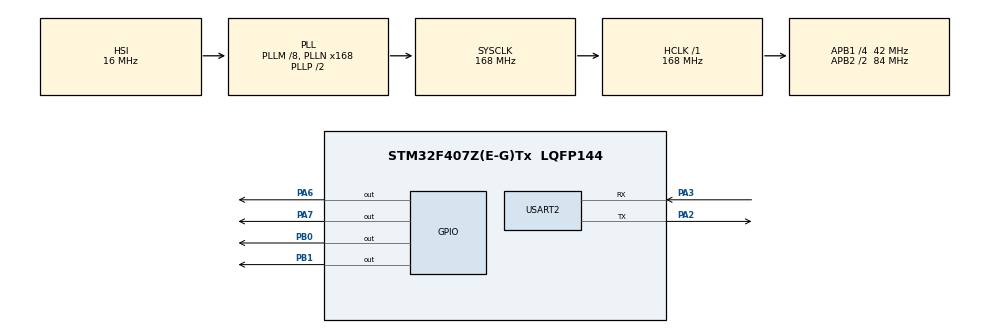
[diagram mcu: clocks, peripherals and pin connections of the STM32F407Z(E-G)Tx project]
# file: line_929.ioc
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Mcu.Family=STM32F4
Mcu.Name=STM32F407Z(E-G)Tx
Mcu.Package=LQFP144
NVIC.PriorityGroup=NVIC_PRIORITYGROUP_4
NVIC.USART2_IRQn=true\:5\:0\:false\:false\:true\:true\:true\:true
PA13.Mode=Serial_Wire
PA13.Signal=SYS_JTMS-SWDIO
PA14.Mode=Serial_Wire
PA14.Signal=SYS_JTCK-SWCLK
PA2.Mode=Asynchronous
PA2.Signal=USART2_TX
PA3.Mode=Asynchronous
PA3.Signal=USART2_RX
PA6.Signal=GPIO_Output
PA7.Signal=GPIO_Output
PB0.Signal=GPIO_Output
PB1.Signal=GPIO_Output
ProjectManager.HeapSize=0x200
ProjectManager.StackSize=0x400
ProjectManager.TargetToolchain=CMake
RCC.48MHZClocksFreq_Value=48000000
RCC.AHBFreq_Value=168000000
RCC.APB1CLKDivider=RCC_HCLK_DIV4
RCC.APB1Freq_Value=42000000
RCC.APB1TimFreq_Value=84000000
RCC.APB2CLKDivider=RCC_HCLK_DIV2
RCC.APB2Freq_Value=84000000
RCC.APB2TimFreq_Value=168000000
RCC.CortexFreq_Value=168000000
RCC.HSE_VALUE=25000000
RCC.HSI_VALUE=16000000
RCC.LSE_VALUE=32768
RCC.PLLM=8
RCC.PLLN=168
RCC.PLLQ=7
RCC.SYSCLKFreq_VALUE=168000000
RCC.SYSCLKSource=RCC_SYSCLKSOURCE_PLLCLK
RCC.VCOOutputFreq_Value=336000000
USART2.VirtualMode=VM_ASYNC
board=custom

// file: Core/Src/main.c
/* USER CODE BEGIN Header */
/**
  ******************************************************************************
  * @file           : main.c
  * @brief          : Main program body
  ******************************************************************************
  * @attention
  *
  * Copyright (c) 2026 STMicroelectronics.
  * All rights reserved.
  *
  * This software is licensed under terms that can be found in the LICENSE file
  * in the root directory of this software component.
  * If no LICENSE file comes with this software, it is provided AS-IS.
  *
  ******************************************************************************
  */
/* USER CODE END Header */
#include "main.h"
#include "usart.h"
#include "gpio.h"

/* USER CODE BEGIN Includes */
#include "oneone_app.h"
#include "oneone_dshot.h"

/* USER CODE END Includes */

/* USER CODE BEGIN PV */
/* Inspect in debugger if the startup banner never appears. */
volatile uint32_t line_929_boot_step = 0U;

/* USER CODE END PV */

void SystemClock_Config(void);

int main(void)
{

  /* MCU Configuration--------------------------------------------------------*/

  /* Reset of all peripherals, Initializes the Flash interface and the Systick. */
  HAL_Init();
  line_929_boot_step = 1U;

  /* Configure the system clock */
  SystemClock_Config();
  line_929_boot_step = 2U;

  /* Initialize all configured peripherals */
  MX_GPIO_Init();
  line_929_boot_step = 3U;
  /* Drive ESC signal pins low before starting the serial control path. */
  OneOneDshot_ForceLow();
  line_929_boot_step = 4U;
  MX_USART2_UART_Init();
  line_929_boot_step = 5U;
  /* USER CODE BEGIN 2 */
  OneOneApp_Init();
  line_929_boot_step = 6U;

  /* USER CODE END 2 */

  /* Infinite loop */
  while (1)
  {

    /* USER CODE BEGIN 3 */
    OneOneApp_Poll();
  }
  /* USER CODE END 3 */
}

void SystemClock_Config(void)
{
  RCC_OscInitTypeDef RCC_OscInitStruct = {0};
  RCC_ClkInitTypeDef RCC_ClkInitStruct = {0};

  /** Configure the main internal regulator output voltage
  */
  __HAL_RCC_PWR_CLK_ENABLE();
  __HAL_PWR_VOLTAGESCALING_CONFIG(PWR_REGULATOR_VOLTAGE_SCALE1);

  /** Initializes the RCC Oscillators according to the specified parameters
  * in the RCC_OscInitTypeDef structure.
  */
  RCC_OscInitStruct.OscillatorType = RCC_OSCILLATORTYPE_HSI;
  RCC_OscInitStruct.HSIState = RCC_HSI_ON;
  RCC_OscInitStruct.HSICalibrationValue = RCC_HSICALIBRATION_DEFAULT;
  RCC_OscInitStruct.PLL.PLLState = RCC_PLL_ON;
  RCC_OscInitStruct.PLL.PLLSource = RCC_PLLSOURCE_HSI;
  RCC_OscInitStruct.PLL.PLLM = 8;
  RCC_OscInitStruct.PLL.PLLN = 168;
  RCC_OscInitStruct.PLL.PLLP = RCC_PLLP_DIV2;
  RCC_OscInitStruct.PLL.PLLQ = 7;
  if (HAL_RCC_OscConfig(&RCC_OscInitStruct) != HAL_OK)
  {
    Error_Handler();
  }

  /** Initializes the CPU, AHB and APB buses clocks
  */
  RCC_ClkInitStruct.ClockType = RCC_CLOCKTYPE_HCLK|RCC_CLOCKTYPE_SYSCLK
                              |RCC_CLOCKTYPE_PCLK1|RCC_CLOCKTYPE_PCLK2;
  RCC_ClkInitStruct.SYSCLKSource = RCC_SYSCLKSOURCE_PLLCLK;
  RCC_ClkInitStruct.AHBCLKDivider = RCC_SYSCLK_DIV1;
  RCC_ClkInitStruct.APB1CLKDivider = RCC_HCLK_DIV4;
  RCC_ClkInitStruct.APB2CLKDivider = RCC_HCLK_DIV2;

  if (HAL_RCC_ClockConfig(&RCC_ClkInitStruct, FLASH_LATENCY_5) != HAL_OK)
  {
    Error_Handler();
  }
}

/* USER CODE BEGIN 4 */
void HAL_UART_RxCpltCallback(UART_HandleTypeDef *huart)
{
  OneOneApp_UartRxComplete(huart);
}

void HAL_UART_ErrorCallback(UART_HandleTypeDef *huart)
{
  OneOneApp_UartError(huart);
}

/* USER CODE END 4 */

void Error_Handler(void)
{
  /* USER CODE BEGIN Error_Handler_Debug */
  OneOneDshot_ForceLow();
  line_929_boot_step |= 0x80000000U;
  __disable_irq();
  while (1)
  {
  }
  /* USER CODE END Error_Handler_Debug */
}
